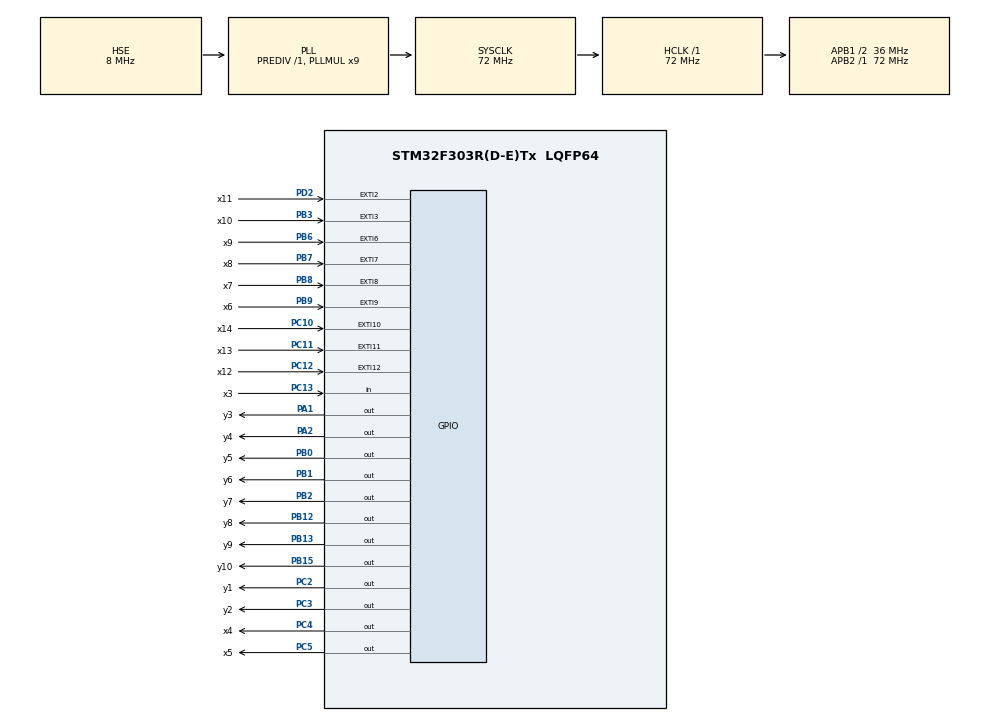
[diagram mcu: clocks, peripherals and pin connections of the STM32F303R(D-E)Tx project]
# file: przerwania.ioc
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Mcu.Family=STM32F3
Mcu.Name=STM32F303R(D-E)Tx
Mcu.Package=LQFP64
NVIC.EXTI15_10_IRQn=true\:0\:0\:false\:false\:true\:true
NVIC.EXTI2_TSC_IRQn=true\:0\:0\:false\:false\:true\:true
NVIC.EXTI3_IRQn=true\:0\:0\:false\:false\:true\:true
NVIC.EXTI9_5_IRQn=true\:0\:0\:false\:false\:true\:true
NVIC.FLASH_IRQn=true\:0\:0\:false\:false\:true\:true
NVIC.FPU_IRQn=true\:0\:0\:false\:false\:true\:true
NVIC.PVD_IRQn=true\:0\:0\:true\:false\:true\:true
NVIC.PriorityGroup=NVIC_PRIORITYGROUP_4
NVIC.RCC_IRQn=true\:0\:0\:false\:false\:true\:true
PA0.Signal=S_TIM2_CH1_ETR
PA1.GPIO_Label=y3
PA1.Signal=GPIO_Output
PA2.GPIO_Label=y4
PA2.Signal=GPIO_Output
PB0.GPIO_Label=y5
PB0.Signal=GPIO_Output
PB1.GPIO_Label=y6
PB1.Signal=GPIO_Output
PB12.GPIO_Label=y8
PB12.Signal=GPIO_Output
PB13.GPIO_Label=y9
PB13.Signal=GPIO_Output
PB15.GPIO_Label=y10
PB15.Signal=GPIO_Output
PB2.GPIO_Label=y7
PB2.Signal=GPIO_Output
PB3.GPIO_Label=x10
PB3.GPIO_ModeDefaultEXTI=GPIO_MODE_IT_RISING_FALLING
PB3.Signal=GPXTI3
PB4.Signal=S_TIM16_CH1
PB5.Signal=S_TIM17_CH1
PB6.GPIO_Label=x9
PB6.GPIO_ModeDefaultEXTI=GPIO_MODE_IT_RISING_FALLING
PB6.Signal=GPXTI6
PB7.GPIO_Label=x8
PB7.GPIO_ModeDefaultEXTI=GPIO_MODE_IT_RISING_FALLING
PB7.Signal=GPXTI7
PB8.GPIO_Label=x7
PB8.GPIO_ModeDefaultEXTI=GPIO_MODE_IT_RISING
PB8.Signal=GPXTI8
PB9.GPIO_Label=x6
PB9.GPIO_ModeDefaultEXTI=GPIO_MODE_IT_RISING_FALLING
PB9.Signal=GPXTI9
PC10.GPIO_Label=x14
PC10.GPIO_ModeDefaultEXTI=GPIO_MODE_IT_RISING_FALLING
PC10.Signal=GPXTI10
PC11.GPIO_Label=x13
PC11.GPIO_ModeDefaultEXTI=GPIO_MODE_IT_RISING_FALLING
PC11.Signal=GPXTI11
PC12.GPIO_Label=x12
PC12.GPIO_ModeDefaultEXTI=GPIO_MODE_IT_RISING_FALLING
PC12.Signal=GPXTI12
PC13.GPIO_Label=x3
PC13.Signal=GPIO_Input
PC14-OSC32_IN.Mode=LSE-External-Oscillator
PC14-OSC32_IN.Signal=RCC_OSC32_IN
PC15-OSC32_OUT.Mode=LSE-External-Oscillator
PC15-OSC32_OUT.Signal=RCC_OSC32_OUT
PC2.GPIO_Label=y1
PC2.Signal=GPIO_Output
PC3.GPIO_Label=y2
PC3.Signal=GPIO_Output
PC4.GPIO_Label=x4
PC4.Signal=GPIO_Output
PC5.GPIO_Label=x5
PC5.Signal=GPIO_Output
PC8.Signal=S_TIM8_CH3
PD2.GPIO_Label=x11
PD2.GPIO_ModeDefaultEXTI=GPIO_MODE_IT_RISING_FALLING
PD2.Signal=GPXTI2
PF0-OSC_IN.Mode=HSE-External-Oscillator
PF0-OSC_IN.Signal=RCC_OSC_IN
PF1-OSC_OUT.Mode=HSE-External-Oscillator
PF1-OSC_OUT.Signal=RCC_OSC_OUT
ProjectManager.HeapSize=0x200
ProjectManager.StackSize=0x400
ProjectManager.TargetToolchain=TrueSTUDIO
RCC.AHBFreq_Value=72000000
RCC.APB1CLKDivider=RCC_HCLK_DIV2
RCC.APB1Freq_Value=36000000
RCC.APB1TimFreq_Value=72000000
RCC.APB2Freq_Value=72000000
RCC.APB2TimFreq_Value=72000000
RCC.CortexFreq_Value=72000000
RCC.HCLKFreq_Value=72000000
RCC.HSE_VALUE=8000000
RCC.HSI_VALUE=8000000
RCC.PLLMUL=RCC_PLL_MUL9
RCC.PLLSourceVirtual=RCC_PLLSOURCE_HSE
RCC.SYSCLKFreq_VALUE=72000000
RCC.SYSCLKSourceVirtual=RCC_SYSCLKSOURCE_PLLCLK
RCC.USBFreq_Value=72000000
SH.S_TIM16_CH1.0=TIM16_CH1
SH.S_TIM17_CH1.0=TIM17_CH1
SH.S_TIM2_CH1_ETR.0=TIM2_CH1
SH.S_TIM8_CH3.0=TIM8_CH3
board=przerwania

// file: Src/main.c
/**
  ******************************************************************************
  * @file           : main.c
  * @brief          : Main program body
  ******************************************************************************
  ** This notice applies to any and all portions of this file
  * that are not between comment pairs USER CODE BEGIN and
  * USER CODE END. Other portions of this file, whether
  * inserted by the user or by software development tools
  * are owned by their respective copyright owners.
  *
  * COPYRIGHT(c) 2019 STMicroelectronics
  *
  * Redistribution and use in source and binary forms, with or without modification,
  * are permitted provided that the following conditions are met:
  *   1. Redistributions of source code must retain the above copyright notice,
  *      this list of conditions and the following disclaimer.
  *   2. Redistributions in binary form must reproduce the above copyright notice,
  *      this list of conditions and the following disclaimer in the documentation
  *      and/or other materials provided with the distribution.
  *   3. Neither the name of STMicroelectronics nor the names of its contributors
  *      may be used to endorse or promote products derived from this software
  *      without specific prior written permission.
  *
  * THIS SOFTWARE IS PROVIDED BY THE COPYRIGHT HOLDERS AND CONTRIBUTORS "AS IS"
  * AND ANY EXPRESS OR IMPLIED WARRANTIES, INCLUDING, BUT NOT LIMITED TO, THE
  * IMPLIED WARRANTIES OF MERCHANTABILITY AND FITNESS FOR A PARTICULAR PURPOSE ARE
  * DISCLAIMED. IN NO EVENT SHALL THE COPYRIGHT HOLDER OR CONTRIBUTORS BE LIABLE
  * FOR ANY DIRECT, INDIRECT, INCIDENTAL, SPECIAL, EXEMPLARY, OR CONSEQUENTIAL
  * DAMAGES (INCLUDING, BUT NOT LIMITED TO, PROCUREMENT OF SUBSTITUTE GOODS OR
  * SERVICES; LOSS OF USE, DATA, OR PROFITS; OR BUSINESS INTERRUPTION) HOWEVER
  * CAUSED AND ON ANY THEORY OF LIABILITY, WHETHER IN CONTRACT, STRICT LIABILITY,
  * OR TORT (INCLUDING NEGLIGENCE OR OTHERWISE) ARISING IN ANY WAY OUT OF THE USE
  * OF THIS SOFTWARE, EVEN IF ADVISED OF THE POSSIBILITY OF SUCH DAMAGE.
  *
  ******************************************************************************
  */
#include "main.h"
#include "stm32f3xx_hal.h"

/* USER CODE BEGIN PV */
/* Private variables ---------------------------------------------------------*/

/* USER CODE END PV */

void SystemClock_Config(void);
static void MX_GPIO_Init(void);

/* USER CODE BEGIN PFP */
/* Private function prototypes -----------------------------------------------*/
void HAL_GPIO_EXTI_Callback(uint16_t GPIO_Pin){
	UNUSED(x7_GPIO_Port);
 if(GPIO_Pin == x7_Pin){
	 HAL_GPIO_WritePin(y8_GPIO_Port, y8_Pin, GPIO_PIN_SET);
 }
}
/* USER CODE END PFP */

int main(void)
{

  /* MCU Configuration----------------------------------------------------------*/

  /* Reset of all peripherals, Initializes the Flash interface and the Systick. */
  HAL_Init();

  /* Configure the system clock */
  SystemClock_Config();

  /* Initialize all configured peripherals */
  MX_GPIO_Init();

  /* Infinite loop */
  /* USER CODE BEGIN WHILE */
  while (1)
  {
	  HAL_GPIO_WritePin(y7_GPIO_Port, y7_Pin, GPIO_PIN_SET);
  /* USER CODE END WHILE */

  }

}

void SystemClock_Config(void)
{

  RCC_OscInitTypeDef RCC_OscInitStruct;
  RCC_ClkInitTypeDef RCC_ClkInitStruct;

    /**Initializes the CPU, AHB and APB busses clocks
    */
  RCC_OscInitStruct.OscillatorType = RCC_OSCILLATORTYPE_HSE;
  RCC_OscInitStruct.HSEState = RCC_HSE_ON;
  RCC_OscInitStruct.HSIState = RCC_HSI_ON;
  RCC_OscInitStruct.PLL.PLLState = RCC_PLL_ON;
  RCC_OscInitStruct.PLL.PLLSource = RCC_PLLSOURCE_HSE;
  RCC_OscInitStruct.PLL.PLLMUL = RCC_PLL_MUL9;
  RCC_OscInitStruct.PLL.PREDIV = RCC_PREDIV_DIV1;
  if (HAL_RCC_OscConfig(&RCC_OscInitStruct) != HAL_OK)
  {
    _Error_Handler(__FILE__, __LINE__);
  }

    /**Initializes the CPU, AHB and APB busses clocks
    */
  RCC_ClkInitStruct.ClockType = RCC_CLOCKTYPE_HCLK|RCC_CLOCKTYPE_SYSCLK
                              |RCC_CLOCKTYPE_PCLK1|RCC_CLOCKTYPE_PCLK2;
  RCC_ClkInitStruct.SYSCLKSource = RCC_SYSCLKSOURCE_PLLCLK;
  RCC_ClkInitStruct.AHBCLKDivider = RCC_SYSCLK_DIV1;
  RCC_ClkInitStruct.APB1CLKDivider = RCC_HCLK_DIV2;
  RCC_ClkInitStruct.APB2CLKDivider = RCC_HCLK_DIV1;

  if (HAL_RCC_ClockConfig(&RCC_ClkInitStruct, FLASH_LATENCY_2) != HAL_OK)
  {
    _Error_Handler(__FILE__, __LINE__);
  }

    /**Configure the Systick interrupt time
    */
  HAL_SYSTICK_Config(HAL_RCC_GetHCLKFreq()/1000);

    /**Configure the Systick
    */
  HAL_SYSTICK_CLKSourceConfig(SYSTICK_CLKSOURCE_HCLK);

  /* SysTick_IRQn interrupt configuration */
  HAL_NVIC_SetPriority(SysTick_IRQn, 0, 0);
}

/** Configure pins as
        * Analog
        * Input
        * Output
        * EVENT_OUT
        * EXTI
     PA0   ------> S_TIM2_CH1_ETR
     PC8   ------> S_TIM8_CH3
     PB4   ------> S_TIM16_CH1
     PB5   ------> S_TIM17_CH1
*/
static void MX_GPIO_Init(void)
{

  GPIO_InitTypeDef GPIO_InitStruct;

  /* GPIO Ports Clock Enable */
  __HAL_RCC_GPIOC_CLK_ENABLE();
  __HAL_RCC_GPIOF_CLK_ENABLE();
  __HAL_RCC_GPIOA_CLK_ENABLE();
  __HAL_RCC_GPIOB_CLK_ENABLE();
  __HAL_RCC_GPIOD_CLK_ENABLE();

  /*Configure GPIO pin Output Level */
  HAL_GPIO_WritePin(GPIOC, y1_Pin|y2_Pin|x4_Pin|x5_Pin, GPIO_PIN_RESET);

  /*Configure GPIO pin Output Level */
  HAL_GPIO_WritePin(GPIOA, y3_Pin|y4_Pin, GPIO_PIN_RESET);

  /*Configure GPIO pin Output Level */
  HAL_GPIO_WritePin(GPIOB, y5_Pin|y6_Pin|y7_Pin|y8_Pin
                          |y9_Pin|y10_Pin, GPIO_PIN_RESET);

  /*Configure GPIO pin : x3_Pin */
  GPIO_InitStruct.Pin = x3_Pin;
  GPIO_InitStruct.Mode = GPIO_MODE_INPUT;
  GPIO_InitStruct.Pull = GPIO_NOPULL;
  HAL_GPIO_Init(x3_GPIO_Port, &GPIO_InitStruct);

  /*Configure GPIO pins : y1_Pin y2_Pin x4_Pin x5_Pin */
  GPIO_InitStruct.Pin = y1_Pin|y2_Pin|x4_Pin|x5_Pin;
  GPIO_InitStruct.Mode = GPIO_MODE_OUTPUT_PP;
  GPIO_InitStruct.Pull = GPIO_NOPULL;
  GPIO_InitStruct.Speed = GPIO_SPEED_FREQ_LOW;
  HAL_GPIO_Init(GPIOC, &GPIO_InitStruct);

  /*Configure GPIO pin : PA0 */
  GPIO_InitStruct.Pin = GPIO_PIN_0;
  GPIO_InitStruct.Mode = GPIO_MODE_AF_PP;
  GPIO_InitStruct.Pull = GPIO_NOPULL;
  GPIO_InitStruct.Speed = GPIO_SPEED_FREQ_LOW;
  GPIO_InitStruct.Alternate = GPIO_AF1_TIM2;
  HAL_GPIO_Init(GPIOA, &GPIO_InitStruct);

  /*Configure GPIO pins : y3_Pin y4_Pin */
  GPIO_InitStruct.Pin = y3_Pin|y4_Pin;
  GPIO_InitStruct.Mode = GPIO_MODE_OUTPUT_PP;
  GPIO_InitStruct.Pull = GPIO_NOPULL;
  GPIO_InitStruct.Speed = GPIO_SPEED_FREQ_LOW;
  HAL_GPIO_Init(GPIOA, &GPIO_InitStruct);

  /*Configure GPIO pins : y5_Pin y6_Pin y7_Pin y8_Pin
                           y9_Pin y10_Pin */
  GPIO_InitStruct.Pin = y5_Pin|y6_Pin|y7_Pin|y8_Pin
                          |y9_Pin|y10_Pin;
  GPIO_InitStruct.Mode = GPIO_MODE_OUTPUT_PP;
  GPIO_InitStruct.Pull = GPIO_NOPULL;
  GPIO_InitStruct.Speed = GPIO_SPEED_FREQ_LOW;
  HAL_GPIO_Init(GPIOB, &GPIO_InitStruct);

  /*Configure GPIO pin : PC8 */
  GPIO_InitStruct.Pin = GPIO_PIN_8;
  GPIO_InitStruct.Mode = GPIO_MODE_AF_PP;
  GPIO_InitStruct.Pull = GPIO_NOPULL;
  GPIO_InitStruct.Speed = GPIO_SPEED_FREQ_LOW;
  GPIO_InitStruct.Alternate = GPIO_AF4_TIM8;
  HAL_GPIO_Init(GPIOC, &GPIO_InitStruct);

  /*Configure GPIO pins : x14_Pin x13_Pin x12_Pin */
  GPIO_InitStruct.Pin = x14_Pin|x13_Pin|x12_Pin;
  GPIO_InitStruct.Mode = GPIO_MODE_IT_RISING_FALLING;
  GPIO_InitStruct.Pull = GPIO_NOPULL;
  HAL_GPIO_Init(GPIOC, &GPIO_InitStruct);

  /*Configure GPIO pin : x11_Pin */
  GPIO_InitStruct.Pin = x11_Pin;
  GPIO_InitStruct.Mode = GPIO_MODE_IT_RISING_FALLING;
  GPIO_InitStruct.Pull = GPIO_NOPULL;
  HAL_GPIO_Init(x11_GPIO_Port, &GPIO_InitStruct);

  /*Configure GPIO pins : x10_Pin x9_Pin x8_Pin x7_Pin
                           x6_Pin */
  GPIO_InitStruct.Pin = x10_Pin|x9_Pin|x8_Pin|x7_Pin
                          |x6_Pin;
  GPIO_InitStruct.Mode = GPIO_MODE_IT_RISING_FALLING;
  GPIO_InitStruct.Pull = GPIO_NOPULL;
  HAL_GPIO_Init(GPIOB, &GPIO_InitStruct);

  /*Configure GPIO pin : PB4 */
  GPIO_InitStruct.Pin = GPIO_PIN_4;
  GPIO_InitStruct.Mode = GPIO_MODE_AF_PP;
  GPIO_InitStruct.Pull = GPIO_NOPULL;
  GPIO_InitStruct.Speed = GPIO_SPEED_FREQ_LOW;
  GPIO_InitStruct.Alternate = GPIO_AF1_TIM16;
  HAL_GPIO_Init(GPIOB, &GPIO_InitStruct);

  /*Configure GPIO pin : PB5 */
  GPIO_InitStruct.Pin = GPIO_PIN_5;
  GPIO_InitStruct.Mode = GPIO_MODE_AF_PP;
  GPIO_InitStruct.Pull = GPIO_NOPULL;
  GPIO_InitStruct.Speed = GPIO_SPEED_FREQ_LOW;
  GPIO_InitStruct.Alternate = GPIO_AF10_TIM17;
  HAL_GPIO_Init(GPIOB, &GPIO_InitStruct);

}

void _Error_Handler(char *file, int line)
{
  while(1)
  {
  }
}

/************************ (C) COPYRIGHT STMicroelectronics *****END OF FILE****/
